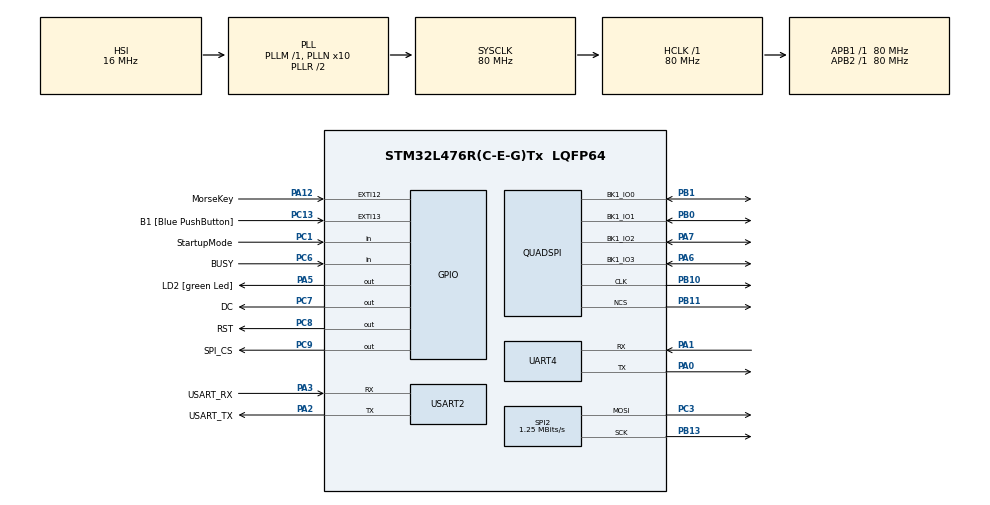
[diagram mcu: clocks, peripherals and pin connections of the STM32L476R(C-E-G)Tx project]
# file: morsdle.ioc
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Mcu.Family=STM32L4
Mcu.Name=STM32L476R(C-E-G)Tx
Mcu.Package=LQFP64
NVIC.EXTI15_10_IRQn=true\:5\:0\:true\:false\:true\:true\:true\:true
NVIC.PriorityGroup=NVIC_PRIORITYGROUP_4
PA0.Mode=Asynchronous
PA0.Signal=UART4_TX
PA1.Mode=Asynchronous
PA1.Signal=UART4_RX
PA12.GPIO_Label=MorseKey
PA12.GPIO_ModeDefaultEXTI=GPIO_MODE_IT_RISING_FALLING
PA12.Signal=GPXTI12
PA13\ (JTMS-SWDIO).GPIO_Label=TMS
PA13\ (JTMS-SWDIO).Mode=Serial_Wire
PA13\ (JTMS-SWDIO).Signal=SYS_JTMS-SWDIO
PA14\ (JTCK-SWCLK).GPIO_Label=TCK
PA14\ (JTCK-SWCLK).Mode=Serial_Wire
PA14\ (JTCK-SWCLK).Signal=SYS_JTCK-SWCLK
PA2.GPIO_Label=USART_TX
PA2.GPIO_Mode=GPIO_MODE_AF_PP
PA2.GPIO_PuPd=GPIO_NOPULL
PA2.GPIO_Speed=GPIO_SPEED_FREQ_VERY_HIGH
PA2.Mode=Asynchronous
PA2.Signal=USART2_TX
PA3.GPIO_Label=USART_RX
PA3.GPIO_Mode=GPIO_MODE_AF_PP
PA3.GPIO_PuPd=GPIO_NOPULL
PA3.GPIO_Speed=GPIO_SPEED_FREQ_VERY_HIGH
PA3.Mode=Asynchronous
PA3.Signal=USART2_RX
PA5.GPIO_Label=LD2 [green Led]
PA5.GPIO_ModeDefaultOutputPP=GPIO_MODE_OUTPUT_PP
PA5.GPIO_PuPd=GPIO_NOPULL
PA5.GPIO_Speed=GPIO_SPEED_FREQ_LOW
PA5.Signal=GPIO_Output
PA6.Mode=Single Bank
PA6.Signal=QUADSPI_BK1_IO3
PA7.Mode=Single Bank
PA7.Signal=QUADSPI_BK1_IO2
PB0.Mode=Single Bank
PB0.Signal=QUADSPI_BK1_IO1
PB1.Mode=Single Bank
PB1.Signal=QUADSPI_BK1_IO0
PB10.Mode=Single Bank
PB10.Signal=QUADSPI_CLK
PB11.Mode=Single Bank
PB11.Signal=QUADSPI_NCS
PB13.Mode=TX_Only_Simplex_Unidirect_Master
PB13.Signal=SPI2_SCK
PB3\ (JTDO-TRACESWO).GPIO_Label=SWO
PB3\ (JTDO-TRACESWO).Signal=SYS_JTDO-SWO
PC1.GPIO_Label=StartupMode
PC1.Signal=GPIO_Input
PC13.GPIO_Label=B1 [Blue PushButton]
PC13.GPIO_ModeDefaultEXTI=GPIO_MODE_IT_RISING_FALLING
PC13.GPIO_PuPd=GPIO_NOPULL
PC13.Signal=GPXTI13
PC14-OSC32_IN\ (PC14).Mode=LSE-External-Oscillator
PC14-OSC32_IN\ (PC14).Signal=RCC_OSC32_IN
PC15-OSC32_OUT\ (PC15).Mode=LSE-External-Oscillator
PC15-OSC32_OUT\ (PC15).Signal=RCC_OSC32_OUT
PC2.Signal=SPI2_MISO
PC3.Mode=TX_Only_Simplex_Unidirect_Master
PC3.Signal=SPI2_MOSI
PC6.GPIO_Label=BUSY
PC6.Signal=GPIO_Input
PC7.GPIO_Label=DC
PC7.Signal=GPIO_Output
PC8.GPIO_Label=RST
PC8.Signal=GPIO_Output
PC9.GPIO_Label=SPI_CS
PC9.Signal=GPIO_Output
PH0-OSC_IN\ (PH0).Signal=RCC_OSC_IN
PH1-OSC_OUT\ (PH1).Signal=RCC_OSC_OUT
ProjectManager.HeapSize=0x200
ProjectManager.StackSize=0x400
ProjectManager.TargetToolchain=Makefile
RCC.ADCFreq_Value=64000000
RCC.AHBFreq_Value=80000000
RCC.APB1Freq_Value=80000000
RCC.APB1TimFreq_Value=80000000
RCC.APB2Freq_Value=80000000
RCC.APB2TimFreq_Value=80000000
RCC.CortexFreq_Value=80000000
RCC.HCLKFreq_Value=80000000
RCC.HSE_VALUE=8000000
RCC.HSI_VALUE=16000000
RCC.MSI_VALUE=4000000
RCC.PLLN=10
RCC.PLLSAI1Q=RCC_PLLQ_DIV4
RCC.PLLSourceVirtual=RCC_PLLSOURCE_HSI
RCC.PREFETCH_ENABLE=1
RCC.SYSCLKFreq_VALUE=80000000
RCC.SYSCLKSource=RCC_SYSCLKSOURCE_PLLCLK
RCC.USBFreq_Value=32000000
RCC.VCOOutputFreq_Value=160000000
SPI2.BaudRatePrescaler=SPI_BAUDRATEPRESCALER_64
SPI2.CRCCalculation=SPI_CRCCALCULATION_DISABLE
SPI2.CalculateBaudRate=1.25 MBits/s
SPI2.DataSize=SPI_DATASIZE_8BIT
SPI2.Direction=SPI_DIRECTION_2LINES
SPI2.Mode=SPI_MODE_MASTER
SPI2.NSSPMode=SPI_NSS_PULSE_DISABLE
SPI2.VirtualType=VM_MASTER
USART2.VirtualMode-Asynchronous=VM_ASYNC
VP_RNG_VS_RNG.Mode=RNG_Activate
VP_TIM1_VS_ClockSourceINT.Mode=Internal
board=NUCLEO-L476RG

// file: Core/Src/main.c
/* USER CODE BEGIN Header */
/**
  ******************************************************************************
  * @file           : main.c
  * @brief          : Main program body
  ******************************************************************************
  * @attention
  *
  * Copyright (c) 2022 STMicroelectronics.
  * All rights reserved.
  *
  * This software is licensed under terms that can be found in the LICENSE file
  * in the root directory of this software component.
  * If no LICENSE file comes with this software, it is provided AS-IS.
  *
  ******************************************************************************
  */
/* USER CODE END Header */
#include "main.h"

/* USER CODE BEGIN Includes */
#include "stm32l4_conf.h"
/* USER CODE END Includes */

 QSPI_HandleTypeDef hqspi;

RNG_HandleTypeDef hrng;

SPI_HandleTypeDef hspi2;

TIM_HandleTypeDef htim1;

UART_HandleTypeDef huart4;
UART_HandleTypeDef huart2;

void SystemClock_Config(void);
static void MX_GPIO_Init(void);
static void MX_SPI2_Init(void);
static void MX_USART2_UART_Init(void);
static void MX_TIM1_Init(void);
static void MX_RNG_Init(void);
static void MX_UART4_Init(void);
static void MX_QUADSPI_Init(void);

void SystemClock_Config(void)
{
  RCC_OscInitTypeDef RCC_OscInitStruct = {0};
  RCC_ClkInitTypeDef RCC_ClkInitStruct = {0};

  /** Configure the main internal regulator output voltage
  */
  if (HAL_PWREx_ControlVoltageScaling(PWR_REGULATOR_VOLTAGE_SCALE1) != HAL_OK)
  {
    Error_Handler();
  }

  /** Initializes the RCC Oscillators according to the specified parameters
  * in the RCC_OscInitTypeDef structure.
  */
  RCC_OscInitStruct.OscillatorType = RCC_OSCILLATORTYPE_HSI;
  RCC_OscInitStruct.HSIState = RCC_HSI_ON;
  RCC_OscInitStruct.HSICalibrationValue = RCC_HSICALIBRATION_DEFAULT;
  RCC_OscInitStruct.PLL.PLLState = RCC_PLL_ON;
  RCC_OscInitStruct.PLL.PLLSource = RCC_PLLSOURCE_HSI;
  RCC_OscInitStruct.PLL.PLLM = 1;
  RCC_OscInitStruct.PLL.PLLN = 10;
  RCC_OscInitStruct.PLL.PLLP = RCC_PLLP_DIV7;
  RCC_OscInitStruct.PLL.PLLQ = RCC_PLLQ_DIV2;
  RCC_OscInitStruct.PLL.PLLR = RCC_PLLR_DIV2;
  if (HAL_RCC_OscConfig(&RCC_OscInitStruct) != HAL_OK)
  {
    Error_Handler();
  }

  /** Initializes the CPU, AHB and APB buses clocks
  */
  RCC_ClkInitStruct.ClockType = RCC_CLOCKTYPE_HCLK|RCC_CLOCKTYPE_SYSCLK
                              |RCC_CLOCKTYPE_PCLK1|RCC_CLOCKTYPE_PCLK2;
  RCC_ClkInitStruct.SYSCLKSource = RCC_SYSCLKSOURCE_PLLCLK;
  RCC_ClkInitStruct.AHBCLKDivider = RCC_SYSCLK_DIV1;
  RCC_ClkInitStruct.APB1CLKDivider = RCC_HCLK_DIV1;
  RCC_ClkInitStruct.APB2CLKDivider = RCC_HCLK_DIV1;

  if (HAL_RCC_ClockConfig(&RCC_ClkInitStruct, FLASH_LATENCY_4) != HAL_OK)
  {
    Error_Handler();
  }
}

static void MX_QUADSPI_Init(void)
{

  /* QUADSPI parameter configuration*/
  hqspi.Instance = QUADSPI;
  hqspi.Init.ClockPrescaler = 255;
  hqspi.Init.FifoThreshold = 1;
  hqspi.Init.SampleShifting = QSPI_SAMPLE_SHIFTING_NONE;
  hqspi.Init.FlashSize = 1;
  hqspi.Init.ChipSelectHighTime = QSPI_CS_HIGH_TIME_1_CYCLE;
  hqspi.Init.ClockMode = QSPI_CLOCK_MODE_0;
  if (HAL_QSPI_Init(&hqspi) != HAL_OK)
  {
    Error_Handler();
  }

}

static void MX_RNG_Init(void)
{

  hrng.Instance = RNG;
  if (HAL_RNG_Init(&hrng) != HAL_OK)
  {
    Error_Handler();
  }

}

static void MX_SPI2_Init(void)
{

  /* SPI2 parameter configuration*/
  hspi2.Instance = SPI2;
  hspi2.Init.Mode = SPI_MODE_MASTER;
  hspi2.Init.Direction = SPI_DIRECTION_2LINES;
  hspi2.Init.DataSize = SPI_DATASIZE_8BIT;
  hspi2.Init.CLKPolarity = SPI_POLARITY_LOW;
  hspi2.Init.CLKPhase = SPI_PHASE_1EDGE;
  hspi2.Init.NSS = SPI_NSS_SOFT;
  hspi2.Init.BaudRatePrescaler = SPI_BAUDRATEPRESCALER_64;
  hspi2.Init.FirstBit = SPI_FIRSTBIT_MSB;
  hspi2.Init.TIMode = SPI_TIMODE_DISABLE;
  hspi2.Init.CRCCalculation = SPI_CRCCALCULATION_DISABLE;
  hspi2.Init.CRCPolynomial = 7;
  hspi2.Init.CRCLength = SPI_CRC_LENGTH_DATASIZE;
  hspi2.Init.NSSPMode = SPI_NSS_PULSE_DISABLE;
  if (HAL_SPI_Init(&hspi2) != HAL_OK)
  {
    Error_Handler();
  }

}

static void MX_TIM1_Init(void)
{

  TIM_ClockConfigTypeDef sClockSourceConfig = {0};
  TIM_MasterConfigTypeDef sMasterConfig = {0};

  htim1.Instance = TIM1;
  htim1.Init.Prescaler = 0;
  htim1.Init.CounterMode = TIM_COUNTERMODE_UP;
  htim1.Init.Period = 65535;
  htim1.Init.ClockDivision = TIM_CLOCKDIVISION_DIV1;
  htim1.Init.RepetitionCounter = 0;
  htim1.Init.AutoReloadPreload = TIM_AUTORELOAD_PRELOAD_DISABLE;
  if (HAL_TIM_Base_Init(&htim1) != HAL_OK)
  {
    Error_Handler();
  }
  sClockSourceConfig.ClockSource = TIM_CLOCKSOURCE_INTERNAL;
  if (HAL_TIM_ConfigClockSource(&htim1, &sClockSourceConfig) != HAL_OK)
  {
    Error_Handler();
  }
  sMasterConfig.MasterOutputTrigger = TIM_TRGO_RESET;
  sMasterConfig.MasterOutputTrigger2 = TIM_TRGO2_RESET;
  sMasterConfig.MasterSlaveMode = TIM_MASTERSLAVEMODE_DISABLE;
  if (HAL_TIMEx_MasterConfigSynchronization(&htim1, &sMasterConfig) != HAL_OK)
  {
    Error_Handler();
  }

}

static void MX_UART4_Init(void)
{

  huart4.Instance = UART4;
  huart4.Init.BaudRate = 115200;
  huart4.Init.WordLength = UART_WORDLENGTH_8B;
  huart4.Init.StopBits = UART_STOPBITS_1;
  huart4.Init.Parity = UART_PARITY_NONE;
  huart4.Init.Mode = UART_MODE_TX_RX;
  huart4.Init.HwFlowCtl = UART_HWCONTROL_NONE;
  huart4.Init.OverSampling = UART_OVERSAMPLING_16;
  huart4.Init.OneBitSampling = UART_ONE_BIT_SAMPLE_DISABLE;
  huart4.AdvancedInit.AdvFeatureInit = UART_ADVFEATURE_NO_INIT;
  if (HAL_UART_Init(&huart4) != HAL_OK)
  {
    Error_Handler();
  }

}

static void MX_USART2_UART_Init(void)
{

  huart2.Instance = USART2;
  huart2.Init.BaudRate = 115200;
  huart2.Init.WordLength = UART_WORDLENGTH_8B;
  huart2.Init.StopBits = UART_STOPBITS_1;
  huart2.Init.Parity = UART_PARITY_NONE;
  huart2.Init.Mode = UART_MODE_TX_RX;
  huart2.Init.HwFlowCtl = UART_HWCONTROL_NONE;
  huart2.Init.OverSampling = UART_OVERSAMPLING_16;
  huart2.Init.OneBitSampling = UART_ONE_BIT_SAMPLE_DISABLE;
  huart2.AdvancedInit.AdvFeatureInit = UART_ADVFEATURE_NO_INIT;
  if (HAL_UART_Init(&huart2) != HAL_OK)
  {
    Error_Handler();
  }

}

static void MX_GPIO_Init(void)
{
  GPIO_InitTypeDef GPIO_InitStruct = {0};

  /* GPIO Ports Clock Enable */
  __HAL_RCC_GPIOC_CLK_ENABLE();
  __HAL_RCC_GPIOH_CLK_ENABLE();
  __HAL_RCC_GPIOA_CLK_ENABLE();
  __HAL_RCC_GPIOB_CLK_ENABLE();

  /*Configure GPIO pin Output Level */
  HAL_GPIO_WritePin(LD2_GPIO_Port, LD2_Pin, GPIO_PIN_RESET);

  /*Configure GPIO pin Output Level */
  HAL_GPIO_WritePin(GPIOC, DC_Pin|RST_Pin|SPI_CS_Pin, GPIO_PIN_RESET);

  /*Configure GPIO pin : B1_Pin */
  GPIO_InitStruct.Pin = B1_Pin;
  GPIO_InitStruct.Mode = GPIO_MODE_IT_RISING_FALLING;
  GPIO_InitStruct.Pull = GPIO_NOPULL;
  HAL_GPIO_Init(B1_GPIO_Port, &GPIO_InitStruct);

  /*Configure GPIO pins : StartupMode_Pin BUSY_Pin */
  GPIO_InitStruct.Pin = StartupMode_Pin|BUSY_Pin;
  GPIO_InitStruct.Mode = GPIO_MODE_INPUT;
  GPIO_InitStruct.Pull = GPIO_NOPULL;
  HAL_GPIO_Init(GPIOC, &GPIO_InitStruct);

  /*Configure GPIO pin : LD2_Pin */
  GPIO_InitStruct.Pin = LD2_Pin;
  GPIO_InitStruct.Mode = GPIO_MODE_OUTPUT_PP;
  GPIO_InitStruct.Pull = GPIO_NOPULL;
  GPIO_InitStruct.Speed = GPIO_SPEED_FREQ_LOW;
  HAL_GPIO_Init(LD2_GPIO_Port, &GPIO_InitStruct);

  /*Configure GPIO pins : DC_Pin RST_Pin SPI_CS_Pin */
  GPIO_InitStruct.Pin = DC_Pin|RST_Pin|SPI_CS_Pin;
  GPIO_InitStruct.Mode = GPIO_MODE_OUTPUT_PP;
  GPIO_InitStruct.Pull = GPIO_NOPULL;
  GPIO_InitStruct.Speed = GPIO_SPEED_FREQ_LOW;
  HAL_GPIO_Init(GPIOC, &GPIO_InitStruct);

  /*Configure GPIO pin : MorseKey_Pin */
  GPIO_InitStruct.Pin = MorseKey_Pin;
  GPIO_InitStruct.Mode = GPIO_MODE_IT_RISING_FALLING;
  GPIO_InitStruct.Pull = GPIO_NOPULL;
  HAL_GPIO_Init(MorseKey_GPIO_Port, &GPIO_InitStruct);

  /* EXTI interrupt init*/
  HAL_NVIC_SetPriority(EXTI15_10_IRQn, 5, 0);
  HAL_NVIC_EnableIRQ(EXTI15_10_IRQn);

}

/* USER CODE BEGIN 4 */
void init_stm32l476()
{
    // this does what the typically generated STM32CubeMX main line does
    HAL_Init();
    SystemClock_Config();
    MX_GPIO_Init();
    MX_SPI2_Init();
    MX_USART2_UART_Init();
    MX_TIM1_Init();
    MX_RNG_Init();
    MX_QUADSPI_Init();
    MX_UART4_Init();
}

/* USER CODE END 4 */

void Error_Handler(void)
{
  __disable_irq();
    while (1)
  {
  }
}
